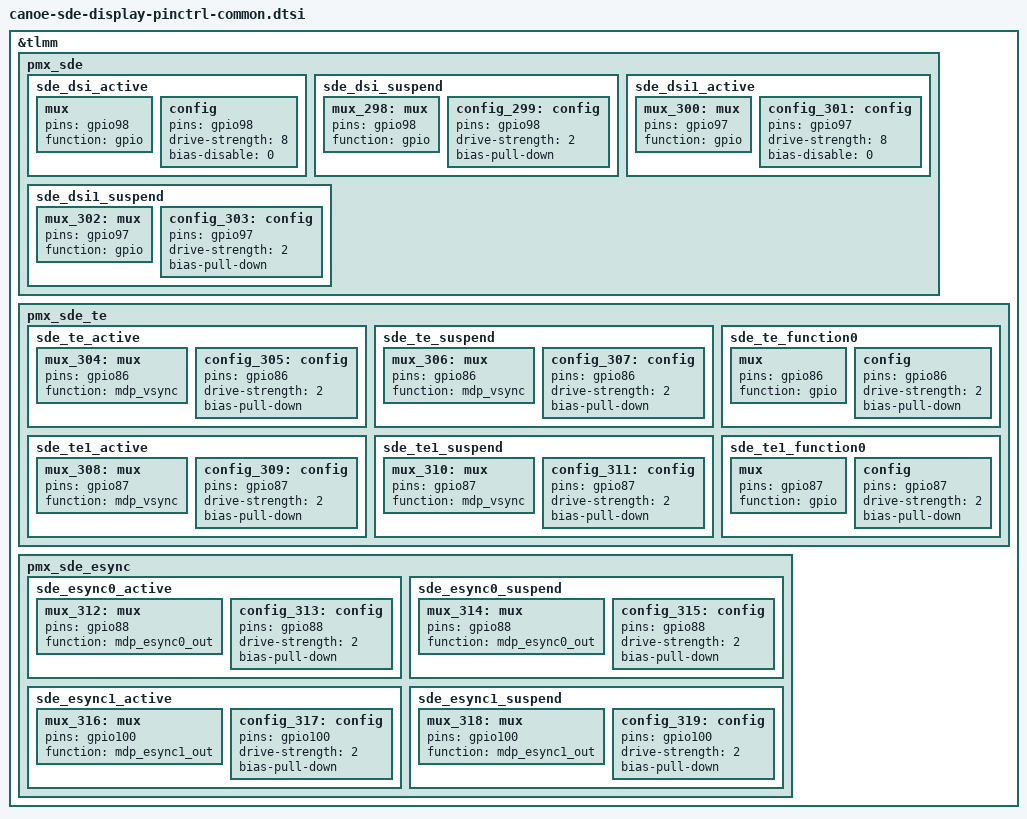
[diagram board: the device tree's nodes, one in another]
// SPDX-License-Identifier: BSD-3-Clause
/*
 * Copyright (c) Qualcomm Technologies, Inc. and/or its subsidiaries.
 */

&tlmm {
	pmx_sde: pmx_sde {
		sde_dsi_active: sde_dsi_active {
			mux: mux {
				pins = "gpio98";
				function = "gpio";
			};

			config: config {
				pins = "gpio98";
				drive-strength = <8>;   /* 8 mA */
				bias-disable = <0>;   /* no pull */
			};
		};

		sde_dsi_suspend: sde_dsi_suspend {
			mux_298: mux {
				pins = "gpio98";
				function = "gpio";
			};

			config_299: config {
				pins = "gpio98";
				drive-strength = <2>;   /* 2 mA */
				bias-pull-down;         /* PULL DOWN */
			};
		};

		sde_dsi1_active: sde_dsi1_active {
			mux_300: mux {
				pins = "gpio97";
				function = "gpio";
			};

			config_301: config {
				pins = "gpio97";
				drive-strength = <8>;   /* 8 mA */
				bias-disable = <0>;   /* no pull */
			};
		};

		sde_dsi1_suspend: sde_dsi1_suspend {
			mux_302: mux {
				pins = "gpio97";
				function = "gpio";
			};

			config_303: config {
				pins = "gpio97";
				drive-strength = <2>;   /* 2 mA */
				bias-pull-down;         /* PULL DOWN */
			};
		};
	};

	pmx_sde_te: pmx_sde_te {
		sde_te_active: sde_te_active {
			mux_304: mux {
				pins = "gpio86";
				function = "mdp_vsync";
			};

			config_305: config {
				pins = "gpio86";
				drive-strength = <2>;   /* 2 mA */
				bias-pull-down;         /* PULL DOWN */
			};
		};

		sde_te_suspend: sde_te_suspend {
			mux_306: mux {
				pins = "gpio86";
				function = "mdp_vsync";
			};

			config_307: config {
				pins = "gpio86";
				drive-strength = <2>;   /* 2 mA */
				bias-pull-down;         /* PULL DOWN */
			};
		};

		sde_te_function0: sde_te_function0 {
			mux {
				pins = "gpio86";
				function = "gpio";
			};

			config {
				pins = "gpio86";
				drive-strength = <2>;   /* 2 mA */
				bias-pull-down;         /* PULL DOWN */
			};
		};

		sde_te1_active: sde_te1_active {
			mux_308: mux {
				pins = "gpio87";
				function = "mdp_vsync";
			};

			config_309: config {
				pins = "gpio87";
				drive-strength = <2>;   /* 2 mA */
				bias-pull-down;         /* PULL DOWN */
			};
		};

		sde_te1_suspend: sde_te1_suspend {
			mux_310: mux {
				pins = "gpio87";
				function = "mdp_vsync";
			};

			config_311: config {
				pins = "gpio87";
				drive-strength = <2>;   /* 2 mA */
				bias-pull-down;         /* PULL DOWN */
			};
		};

		sde_te1_function0: sde_te1_function0 {
			mux {
				pins = "gpio87";
				function = "gpio";
			};

			config {
				pins = "gpio87";
				drive-strength = <2>;   /* 2 mA */
				bias-pull-down;         /* PULL DOWN */
			};
		};
	};

	pmx_sde_esync: pmx_sde_esync {
		sde_esync0_active: sde_esync0_active {
			mux_312: mux {
				pins = "gpio88";
				function = "mdp_esync0_out";
			};

			config_313: config {
				pins = "gpio88";
				drive-strength = <2>;   /* 2 mA */
				bias-pull-down;         /* PULL DOWN */
			};
		};

		sde_esync0_suspend: sde_esync0_suspend {
			mux_314: mux {
				pins = "gpio88";
				function = "mdp_esync0_out";
			};

			config_315: config {
				pins = "gpio88";
				drive-strength = <2>;   /* 2 mA */
				bias-pull-down;         /* PULL DOWN */
			};
		};

		sde_esync1_active: sde_esync1_active {
			mux_316: mux {
				pins = "gpio100";
				function = "mdp_esync1_out";
			};

			config_317: config {
				pins = "gpio100";
				drive-strength = <2>;   /* 2 mA */
				bias-pull-down;         /* PULL DOWN */
			};
		};

		sde_esync1_suspend: sde_esync1_suspend {
			mux_318: mux {
				pins = "gpio100";
				function = "mdp_esync1_out";
			};

			config_319: config {
				pins = "gpio100";
				drive-strength = <2>;   /* 2 mA */
				bias-pull-down;         /* PULL DOWN */
			};
		};
	};
};
